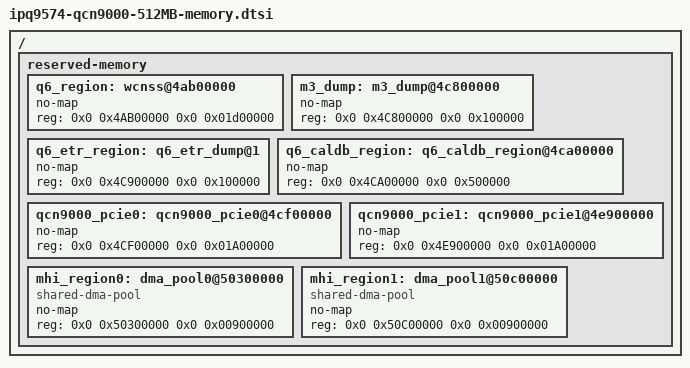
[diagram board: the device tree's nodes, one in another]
// SPDX-License-Identifier: (GPL-2.0+ OR BSD-3-Clause)
/*
 * IPQ9574 Memory device tree source
 *
 * Copyright (c) 2021 The Linux Foundation. All rights reserved.
 * Copyright (c) 2024 Qualcomm Innovation Center, Inc. All rights reserved.
*/

/ {
	/*		  512 MB Profile
	 * +=========+==============+========================+
	 * |        |              |                         |
	 * | Region | Start Offset |          Size           |
	 * |        |              |                         |
	 * +--------+--------------+-------------------------+
	 * |        |              |                         |
	 * |        |              |                         |
	 * | WLAN   |              |                         |
	 * |   Q6   |  0x4AB00000  |          29MB           |
	 * |        |              |                         |
	 * |        |              |                         |
	 * +--------+--------------+-------------------------+
	 * | M3 Dump|  0x4C800000  |           1MB           |
	 * +--------+--------------+-------------------------+
	 * | WLAN   |              |                         |
	 * | Q6 ETR |  0x4C900000  |           1MB           |
	 * | Region |              |                         |
	 * +--------+--------------+-------------------------+
	 * | caldb  |  0x4CA00000  |           5MB           |
	 * +--------+--------------+-------------------------+
	 * |        |              |                         |
	 * |  Pine1 |  0x4CF00000  |          26MB           |
	 * |        |              |                         |
	 * +--------+--------------+-------------------------+
	 * |        |              |                         |
	 * |  Pine2 |  0x4E900000  |          26MB           |
	 * |        |              |                         |
	 * +--------+--------------+-------------------------+
	 * |        |              |                         |
	 * |  MHI1  |  0x50300000  |           9MB           |
	 * |        |              |                         |
	 * +--------+--------------+-------------------------+
	 * |        |              |                         |
	 * |  MHI2  |  0x50C00000  |           9MB           |
	 * |        |              |                         |
	 * +=================================================+
	 * |                                                 |
	 * |                                                 |
	 * |                                                 |
	 * |            Rest of memory for Linux             |
	 * |                                                 |
	 * |                                                 |
	 * |                                                 |
	 * +=================================================+
	 */

	reserved-memory {
		#address-cells = <2>;
		#size-cells = <2>;
		ranges;

		q6_region: wcnss@4ab00000 {
			no-map;
			reg = <0x0 0x4AB00000 0x0 0x01d00000>;
		};

		m3_dump: m3_dump@4c800000 {
			no-map;
			reg = <0x0 0x4C800000 0x0 0x100000>;
		};

		q6_etr_region: q6_etr_dump@1 {
			no-map;
			reg = <0x0 0x4C900000 0x0 0x100000>;
		};

		q6_caldb_region:q6_caldb_region@4ca00000 {
			no-map;
			reg = <0x0 0x4CA00000 0x0 0x500000>;
		};

		qcn9000_pcie0: qcn9000_pcie0@4cf00000 {
			no-map;
			reg = <0x0 0x4CF00000 0x0 0x01A00000>;
		};

		qcn9000_pcie1: qcn9000_pcie1@4e900000 {
			no-map;
			reg = <0x0 0x4E900000 0x0 0x01A00000>;
		};

		mhi_region0: dma_pool0@50300000 {
			compatible = "shared-dma-pool";
			no-map;
			reg = <0x0 0x50300000 0x0 0x00900000>;
		};

		mhi_region1: dma_pool1@50c00000 {
			compatible = "shared-dma-pool";
			no-map;
			reg = <0x0 0x50C00000 0x0 0x00900000>;
		};
	};
};
